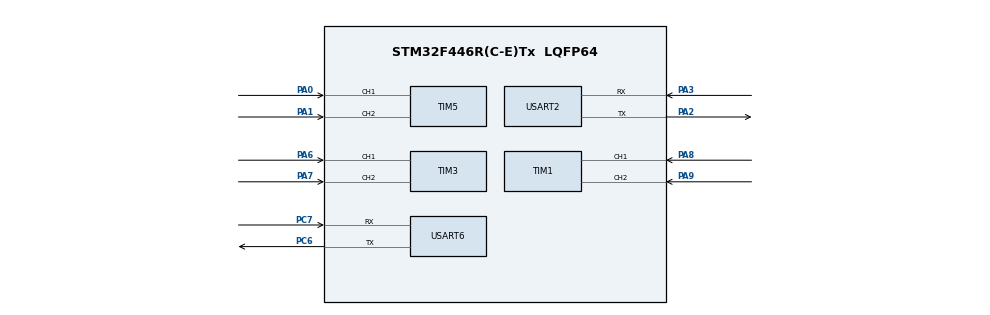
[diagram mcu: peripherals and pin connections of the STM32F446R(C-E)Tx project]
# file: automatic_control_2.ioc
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Mcu.Family=STM32F4
Mcu.Name=STM32F446R(C-E)Tx
Mcu.Package=LQFP64
NVIC.PriorityGroup=NVIC_PRIORITYGROUP_4
NVIC.TIM6_DAC_IRQn=true\:0\:0\:false\:false\:true\:true\:true
NVIC.USART2_IRQn=true\:0\:0\:false\:false\:true\:true\:true
PA0-WKUP.Signal=S_TIM5_CH1
PA1.Signal=S_TIM5_CH2
PA2.Mode=Asynchronous
PA2.Signal=USART2_TX
PA3.Mode=Asynchronous
PA3.Signal=USART2_RX
PA6.Signal=S_TIM3_CH1
PA7.Signal=S_TIM3_CH2
PA8.Signal=S_TIM1_CH1
PA9.Signal=S_TIM1_CH2
PC6.Mode=Asynchronous
PC6.Signal=USART6_TX
PC7.Mode=Asynchronous
PC7.Signal=USART6_RX
ProjectManager.HeapSize=0x200
ProjectManager.StackSize=0x400
ProjectManager.TargetToolchain=STM32CubeIDE
RCC.CortexFreq_Value=16000000
RCC.USBFreq_Value=96000000
RCC.VCOOutputFreq_Value=192000000
SH.S_TIM1_CH1.0=TIM1_CH1,Encoder_Interface
SH.S_TIM1_CH2.0=TIM1_CH2,Encoder_Interface
SH.S_TIM3_CH1.0=TIM3_CH1,Encoder_Interface
SH.S_TIM3_CH2.0=TIM3_CH2,Encoder_Interface
SH.S_TIM5_CH1.0=TIM5_CH1,Encoder_Interface
SH.S_TIM5_CH2.0=TIM5_CH2,Encoder_Interface
TIM1.EncoderMode=TIM_ENCODERMODE_TI12
TIM3.EncoderMode=TIM_ENCODERMODE_TI12
TIM5.EncoderMode=TIM_ENCODERMODE_TI12
TIM6.AutoReloadPreload=TIM_AUTORELOAD_PRELOAD_ENABLE
TIM6.Period=1600
TIM6.Prescaler=10000
USART2.VirtualMode=VM_ASYNC
USART6.VirtualMode=VM_ASYNC
VP_TIM6_VS_ClockSourceINT.Mode=Enable_Timer
board=custom

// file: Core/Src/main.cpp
/* USER CODE BEGIN Header */
/**
  ******************************************************************************
  * @file           : main.c
  * @brief          : Main program body
  ******************************************************************************
  * @attention
  *
  * <h2><center>&copy; Copyright (c) 2021 STMicroelectronics.
  * All rights reserved.</center></h2>
  *
  * This software component is licensed by ST under BSD 3-Clause license,
  * the "License"; You may not use this file except in compliance with the
  * License. You may obtain a copy of the License at:
  *                        opensource.org/licenses/BSD-3-Clause
  *
  ******************************************************************************
  */
/* USER CODE END Header */
#include "main.h"

/* USER CODE BEGIN Includes */
#include "Motor.hpp"
#include "PWM.hpp"
/* USER CODE END Includes */

TIM_HandleTypeDef htim1;
TIM_HandleTypeDef htim3;
TIM_HandleTypeDef htim5;
TIM_HandleTypeDef htim6;

UART_HandleTypeDef huart2;
UART_HandleTypeDef huart6;

void SystemClock_Config(void);
static void MX_GPIO_Init(void);
static void MX_TIM1_Init(void);
static void MX_TIM3_Init(void);
static void MX_TIM5_Init(void);
static void MX_TIM6_Init(void);
static void MX_USART2_UART_Init(void);
static void MX_USART6_UART_Init(void);

int main(void)
{

  /* MCU Configuration--------------------------------------------------------*/

  /* Reset of all peripherals, Initializes the Flash interface and the Systick. */
  HAL_Init();

  /* Configure the system clock */
  SystemClock_Config();

  /* Initialize all configured peripherals */
  MX_GPIO_Init();
  MX_TIM1_Init();
  MX_TIM3_Init();
  MX_TIM5_Init();
  MX_TIM6_Init();
  MX_USART2_UART_Init();
  MX_USART6_UART_Init();
  /* USER CODE BEGIN 2 */
  Motor* motor = new Motor();
  /* USER CODE END 2 */

  /* Infinite loop */
  /* USER CODE BEGIN WHILE */
  while (1)
  {
	  motor -> drive_motor(1, 1, 30);
	  HAL_Delay(100);
    /* USER CODE END WHILE */

  }
}

void SystemClock_Config(void)
{
  RCC_OscInitTypeDef RCC_OscInitStruct = {0};
  RCC_ClkInitTypeDef RCC_ClkInitStruct = {0};

  /** Configure the main internal regulator output voltage
  */
  __HAL_RCC_PWR_CLK_ENABLE();
  __HAL_PWR_VOLTAGESCALING_CONFIG(PWR_REGULATOR_VOLTAGE_SCALE3);
  /** Initializes the RCC Oscillators according to the specified parameters
  * in the RCC_OscInitTypeDef structure.
  */
  RCC_OscInitStruct.OscillatorType = RCC_OSCILLATORTYPE_HSI;
  RCC_OscInitStruct.HSIState = RCC_HSI_ON;
  RCC_OscInitStruct.HSICalibrationValue = RCC_HSICALIBRATION_DEFAULT;
  RCC_OscInitStruct.PLL.PLLState = RCC_PLL_NONE;
  if (HAL_RCC_OscConfig(&RCC_OscInitStruct) != HAL_OK)
  {
    Error_Handler();
  }
  /** Initializes the CPU, AHB and APB buses clocks
  */
  RCC_ClkInitStruct.ClockType = RCC_CLOCKTYPE_HCLK|RCC_CLOCKTYPE_SYSCLK
                              |RCC_CLOCKTYPE_PCLK1|RCC_CLOCKTYPE_PCLK2;
  RCC_ClkInitStruct.SYSCLKSource = RCC_SYSCLKSOURCE_HSI;
  RCC_ClkInitStruct.AHBCLKDivider = RCC_SYSCLK_DIV1;
  RCC_ClkInitStruct.APB1CLKDivider = RCC_HCLK_DIV1;
  RCC_ClkInitStruct.APB2CLKDivider = RCC_HCLK_DIV1;

  if (HAL_RCC_ClockConfig(&RCC_ClkInitStruct, FLASH_LATENCY_0) != HAL_OK)
  {
    Error_Handler();
  }
}

static void MX_TIM1_Init(void)
{

  TIM_Encoder_InitTypeDef sConfig = {0};
  TIM_MasterConfigTypeDef sMasterConfig = {0};

  htim1.Instance = TIM1;
  htim1.Init.Prescaler = 0;
  htim1.Init.CounterMode = TIM_COUNTERMODE_UP;
  htim1.Init.Period = 65535;
  htim1.Init.ClockDivision = TIM_CLOCKDIVISION_DIV1;
  htim1.Init.RepetitionCounter = 0;
  htim1.Init.AutoReloadPreload = TIM_AUTORELOAD_PRELOAD_DISABLE;
  sConfig.EncoderMode = TIM_ENCODERMODE_TI12;
  sConfig.IC1Polarity = TIM_ICPOLARITY_RISING;
  sConfig.IC1Selection = TIM_ICSELECTION_DIRECTTI;
  sConfig.IC1Prescaler = TIM_ICPSC_DIV1;
  sConfig.IC1Filter = 0;
  sConfig.IC2Polarity = TIM_ICPOLARITY_RISING;
  sConfig.IC2Selection = TIM_ICSELECTION_DIRECTTI;
  sConfig.IC2Prescaler = TIM_ICPSC_DIV1;
  sConfig.IC2Filter = 0;
  if (HAL_TIM_Encoder_Init(&htim1, &sConfig) != HAL_OK)
  {
    Error_Handler();
  }
  sMasterConfig.MasterOutputTrigger = TIM_TRGO_RESET;
  sMasterConfig.MasterSlaveMode = TIM_MASTERSLAVEMODE_DISABLE;
  if (HAL_TIMEx_MasterConfigSynchronization(&htim1, &sMasterConfig) != HAL_OK)
  {
    Error_Handler();
  }

}

static void MX_TIM3_Init(void)
{

  TIM_Encoder_InitTypeDef sConfig = {0};
  TIM_MasterConfigTypeDef sMasterConfig = {0};

  htim3.Instance = TIM3;
  htim3.Init.Prescaler = 0;
  htim3.Init.CounterMode = TIM_COUNTERMODE_UP;
  htim3.Init.Period = 65535;
  htim3.Init.ClockDivision = TIM_CLOCKDIVISION_DIV1;
  htim3.Init.AutoReloadPreload = TIM_AUTORELOAD_PRELOAD_DISABLE;
  sConfig.EncoderMode = TIM_ENCODERMODE_TI12;
  sConfig.IC1Polarity = TIM_ICPOLARITY_RISING;
  sConfig.IC1Selection = TIM_ICSELECTION_DIRECTTI;
  sConfig.IC1Prescaler = TIM_ICPSC_DIV1;
  sConfig.IC1Filter = 0;
  sConfig.IC2Polarity = TIM_ICPOLARITY_RISING;
  sConfig.IC2Selection = TIM_ICSELECTION_DIRECTTI;
  sConfig.IC2Prescaler = TIM_ICPSC_DIV1;
  sConfig.IC2Filter = 0;
  if (HAL_TIM_Encoder_Init(&htim3, &sConfig) != HAL_OK)
  {
    Error_Handler();
  }
  sMasterConfig.MasterOutputTrigger = TIM_TRGO_RESET;
  sMasterConfig.MasterSlaveMode = TIM_MASTERSLAVEMODE_DISABLE;
  if (HAL_TIMEx_MasterConfigSynchronization(&htim3, &sMasterConfig) != HAL_OK)
  {
    Error_Handler();
  }

}

static void MX_TIM5_Init(void)
{

  TIM_Encoder_InitTypeDef sConfig = {0};
  TIM_MasterConfigTypeDef sMasterConfig = {0};

  htim5.Instance = TIM5;
  htim5.Init.Prescaler = 0;
  htim5.Init.CounterMode = TIM_COUNTERMODE_UP;
  htim5.Init.Period = 4294967295;
  htim5.Init.ClockDivision = TIM_CLOCKDIVISION_DIV1;
  htim5.Init.AutoReloadPreload = TIM_AUTORELOAD_PRELOAD_DISABLE;
  sConfig.EncoderMode = TIM_ENCODERMODE_TI12;
  sConfig.IC1Polarity = TIM_ICPOLARITY_RISING;
  sConfig.IC1Selection = TIM_ICSELECTION_DIRECTTI;
  sConfig.IC1Prescaler = TIM_ICPSC_DIV1;
  sConfig.IC1Filter = 0;
  sConfig.IC2Polarity = TIM_ICPOLARITY_RISING;
  sConfig.IC2Selection = TIM_ICSELECTION_DIRECTTI;
  sConfig.IC2Prescaler = TIM_ICPSC_DIV1;
  sConfig.IC2Filter = 0;
  if (HAL_TIM_Encoder_Init(&htim5, &sConfig) != HAL_OK)
  {
    Error_Handler();
  }
  sMasterConfig.MasterOutputTrigger = TIM_TRGO_RESET;
  sMasterConfig.MasterSlaveMode = TIM_MASTERSLAVEMODE_DISABLE;
  if (HAL_TIMEx_MasterConfigSynchronization(&htim5, &sMasterConfig) != HAL_OK)
  {
    Error_Handler();
  }

}

static void MX_TIM6_Init(void)
{

  TIM_MasterConfigTypeDef sMasterConfig = {0};

  htim6.Instance = TIM6;
  htim6.Init.Prescaler = 10000;
  htim6.Init.CounterMode = TIM_COUNTERMODE_UP;
  htim6.Init.Period = 1600;
  htim6.Init.AutoReloadPreload = TIM_AUTORELOAD_PRELOAD_ENABLE;
  if (HAL_TIM_Base_Init(&htim6) != HAL_OK)
  {
    Error_Handler();
  }
  sMasterConfig.MasterOutputTrigger = TIM_TRGO_RESET;
  sMasterConfig.MasterSlaveMode = TIM_MASTERSLAVEMODE_DISABLE;
  if (HAL_TIMEx_MasterConfigSynchronization(&htim6, &sMasterConfig) != HAL_OK)
  {
    Error_Handler();
  }

}

static void MX_USART2_UART_Init(void)
{

  huart2.Instance = USART2;
  huart2.Init.BaudRate = 115200;
  huart2.Init.WordLength = UART_WORDLENGTH_8B;
  huart2.Init.StopBits = UART_STOPBITS_1;
  huart2.Init.Parity = UART_PARITY_NONE;
  huart2.Init.Mode = UART_MODE_TX_RX;
  huart2.Init.HwFlowCtl = UART_HWCONTROL_NONE;
  huart2.Init.OverSampling = UART_OVERSAMPLING_16;
  if (HAL_UART_Init(&huart2) != HAL_OK)
  {
    Error_Handler();
  }

}

static void MX_USART6_UART_Init(void)
{

  huart6.Instance = USART6;
  huart6.Init.BaudRate = 115200;
  huart6.Init.WordLength = UART_WORDLENGTH_8B;
  huart6.Init.StopBits = UART_STOPBITS_1;
  huart6.Init.Parity = UART_PARITY_NONE;
  huart6.Init.Mode = UART_MODE_TX_RX;
  huart6.Init.HwFlowCtl = UART_HWCONTROL_NONE;
  huart6.Init.OverSampling = UART_OVERSAMPLING_16;
  if (HAL_UART_Init(&huart6) != HAL_OK)
  {
    Error_Handler();
  }

}

static void MX_GPIO_Init(void)
{

  /* GPIO Ports Clock Enable */
  __HAL_RCC_GPIOA_CLK_ENABLE();
  __HAL_RCC_GPIOC_CLK_ENABLE();

}

void Error_Handler(void)
{
  __disable_irq();
  while (1)
  {
  }
}

/************************ (C) COPYRIGHT STMicroelectronics *****END OF FILE****/
